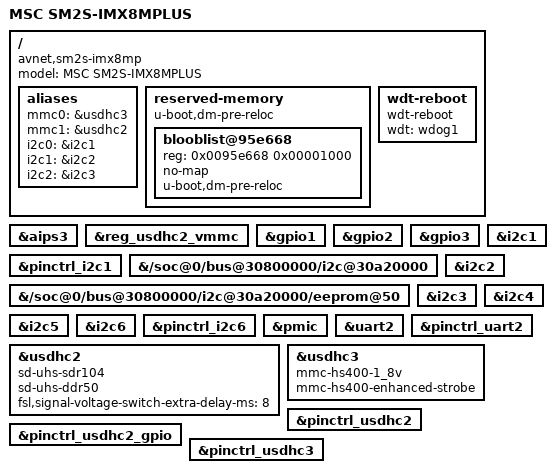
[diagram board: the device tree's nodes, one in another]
// SPDX-License-Identifier: GPL-2.0+
/*
 * Copyright 2019 NXP
 */

#include "imx8mp-u-boot.dtsi"

/ {
	model = "MSC SM2S-IMX8MPLUS";
	compatible = "avnet,sm2s-imx8mp", "fsl,imx8mp";

	aliases {
		mmc0 = &usdhc3;
		mmc1 = &usdhc2;
		i2c0 = &i2c1;
		i2c1 = &i2c2;
		i2c2 = &i2c3;
	};

	reserved-memory {
		u-boot,dm-pre-reloc;

		blooblist@95e668 {
			reg = <0x0095e668 0x00001000>;
			no-map;
			u-boot,dm-pre-reloc;
		};
	};

	wdt-reboot {
		compatible = "wdt-reboot";
		wdt = <&wdog1>;
		bootph-pre-ram;
	};
};

&aips3 {
	bootph-pre-ram;
};

&reg_usdhc2_vmmc {
	bootph-pre-ram;
};

&gpio1 {
	bootph-pre-ram;
};

&gpio2 {
	bootph-pre-ram;
};

&gpio3 {
	bootph-pre-ram;
};

&i2c1 {
	bootph-pre-ram;
};

&pinctrl_i2c1 {
	bootph-pre-ram;
};

&{/soc@0/bus@30800000/i2c@30a20000} {
	bootph-pre-ram;
};

&{/soc@0/bus@30800000/i2c@30a20000/eeprom@50} {
	bootph-pre-ram;
};

&i2c2 {
	bootph-pre-ram;
};

&i2c3 {
	bootph-pre-ram;
};

&i2c4 {
	bootph-pre-ram;
};

&i2c5 {
	bootph-pre-ram;
};

&i2c6 {
	bootph-pre-ram;
};

&pinctrl_i2c6 {
	bootph-pre-ram;
};

&pmic {
	bootph-pre-ram;
};

&uart2 {
	bootph-pre-ram;
};

&pinctrl_uart2 {
	bootph-pre-ram;
};

&usdhc2 {
	bootph-pre-ram;
	sd-uhs-sdr104;
	sd-uhs-ddr50;
	fsl,signal-voltage-switch-extra-delay-ms = <8>;
};

&usdhc3 {
	bootph-pre-ram;
	mmc-hs400-1_8v;
	mmc-hs400-enhanced-strobe;
};

&pinctrl_usdhc2 {
	bootph-pre-ram;
};

&pinctrl_usdhc2_gpio {
	bootph-pre-ram;
};

&pinctrl_usdhc3 {
	bootph-pre-ram;
};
